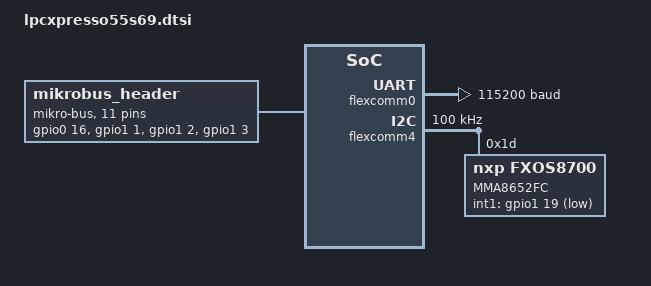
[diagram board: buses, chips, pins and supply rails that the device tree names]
/*
 * Copyright (c) 2019, NXP
 *
 * SPDX-License-Identifier: Apache-2.0
 */

/ {
	aliases{
		led0 = &red_led;
		led1 = &green_led;
		led2 = &blue_led;
		spi-8 = &hs_lspi;
		usart-0 = &flexcomm0;
	};

	leds {
		compatible = "gpio-leds";
		green_led: led_1 {
			gpios = <&gpio1 7 0>;
			label = "User LD2";
			status = "disabled";
		};
		blue_led: led_2 {
			gpios = <&gpio1 4 0>;
			label = "User LD3";
			status = "disabled";
		};
		red_led: led_3 {
			gpios = <&gpio1 6 0>;
			label = "User LD4";
			status = "disabled";
		};
	};

	mikrobus_header: mikrobus-connector {
		compatible = "mikro-bus";
		#gpio-cells = <2>;
		gpio-map-mask = <0xffffffff 0xffffffc0>;
		gpio-map-pass-thru = <0 0x3f>;
		gpio-map =	<0 0 &gpio0 16 0>,	/* AN  */
				/* Not a GPIO*/		/* RST */
				<2 0 &gpio1 1 0>,	/* CS   */
				<3 0 &gpio1 2 0>,	/* SCK  */
				<4 0 &gpio1 3 0>,	/* MISO */
				<5 0 &gpio0 26 0>,	/* MOSI */
							/* +3.3V */
							/* GND */
				<6 0 &gpio1 15 0>,	/* PWM  */
				<7 0 &gpio1 18 0>,	/* INT  */
				<8 0 &gpio0 27 0>,	/* RX   */
				<9 0 &gpio1 24 0>,	/* TX   */
				<10 0 &gpio1 20 0>,	/* SCL  */
				<11 0 &gpio1 21 0>;	/* SDA  */
							/* +5V */
							/* GND */
	};
};

&flexcomm0 {
	compatible = "nxp,lpc-usart";
	current-speed = <115200>;
};

arduino_i2c: &flexcomm4 {
	compatible = "nxp,lpc-i2c";
	clock-frequency = <I2C_BITRATE_STANDARD>;
	#address-cells = <1>;
	#size-cells = <0>;

	mma8652fc@1d {
		compatible = "nxp,fxos8700","nxp,mma8652fc";
		reg = <0x1d>;
		label = "MMA8652FC";
		int1-gpios = <&gpio1 19 GPIO_ACTIVE_LOW>;
	};
};

arduino_spi: &hs_lspi {
};

mikrobus_spi: &hs_lspi {
};
